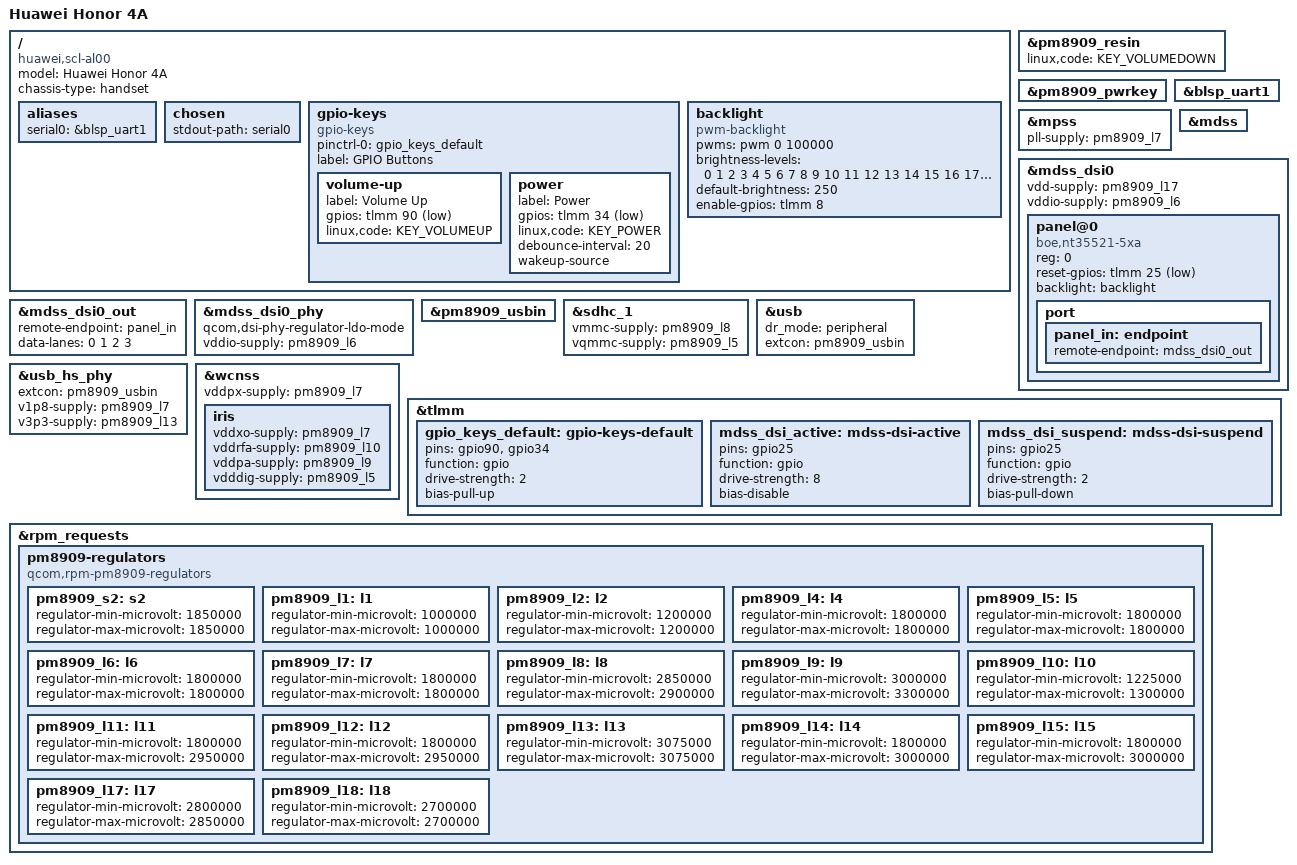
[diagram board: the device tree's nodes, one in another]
// SPDX-License-Identifier: GPL-2.0-only
/*
 * Copyright (c) 2022 Twodays <gunmu114514@outlook.com>
 */
#include "qcom-msm8909.dtsi"
#include "qcom-pm8909.dtsi"
#include <dt-bindings/input/input.h>
#include <dt-bindings/gpio/gpio.h>

/ {
	model = "Huawei Honor 4A";
	compatible = "huawei,scl-al00", "qcom,msm8909";
	chassis-type = "handset";

	aliases {
		serial0 = &blsp_uart1;
	};

	chosen {
		stdout-path = "serial0";
	};

	gpio-keys {
		compatible = "gpio-keys";

		pinctrl-names = "default";
		pinctrl-0 = <&gpio_keys_default>;

		label = "GPIO Buttons";

		volume-up {
			label = "Volume Up";
			gpios = <&tlmm 90 GPIO_ACTIVE_LOW>;
			linux,code = <KEY_VOLUMEUP>;
		};

		power {
			label = "Power";
			gpios = <&tlmm 34 GPIO_ACTIVE_LOW>;
			linux,code = <KEY_POWER>;
			debounce-interval = <20>;
			wakeup-source;
		};
	};

	backlight: backlight {
		compatible = "pwm-backlight";
		pwms = <&pwm 0 100000>;
		brightness-levels = <0 1 2 3 4 5 6 7 8 9 10 11 12 13 14 15
				     16 17 18 19 20 21 22 23 24 25 26 27 28 29 30
				     31 32 33 34 35 36 37 38 39 40 41 42 43 44 45
				     46 47 48 49 50 51 52 53 54 55 56 57 58 59 60
				     61 62 63 64 65 66 67 68 69 70 71 72 73 74 75
				     76 77 78 79 80 81 82 83 84 85 86 87 88 89 90
				     91 92 93 94 95 96 97 98 99 100 101 102 103 104
				     105 106 107 108 109 110 111 112 113 114 115 116
				     117 118 119 120 121 122 123 124 125 126 127 128
				     129 130 131 132 133 134 135 136 137 138 139 140
				     141 142 143 144 145 146 147 148 149 150 151 152
				     153 154 155 156 157 158 159 160 161 162 163 164
				     165 166 167 168 169 170 171 172 173 174 175 176
				     177 178 179 180 181 182 183 184 185 186 187 188
				     189 190 191 192 193 194 195 196 197 198 199 200
				     201 202 203 204 205 206 207 208 209 210 211 212
				     213 214 215 216 217 218 219 220 221 222 223 224
				     225 226 227 228 229 230 231 232 233 234 235 236
				     237 238 239 240 241 242 243 244 245 246 247 248
				     249 250>;
		default-brightness = <250>;
		enable-gpios = <&tlmm 8 GPIO_ACTIVE_HIGH>;
	};
};

&pm8909_resin {
	status = "okay";
	linux,code = <KEY_VOLUMEDOWN>;
};

&pm8909_pwrkey {
	status = "okay";
};

&blsp_uart1 {
	status = "okay";
};

&mpss {
	status = "okay";
	pll-supply = <&pm8909_l7>;
};

&mdss {
	status = "okay";
};

&mdss_dsi0 {
	status = "okay";
	vdd-supply = <&pm8909_l17>;
	vddio-supply = <&pm8909_l6>;
	
	#address-cells = <1>;
	#size-cells = <0>;
	
	panel@0 {
		compatible = "boe,nt35521-5xa";
		reg = <0>;
		
		reset-gpios = <&tlmm 25 GPIO_ACTIVE_LOW>;
		backlight = <&backlight>;
		
		port {
			panel_in: endpoint {
				remote-endpoint = <&mdss_dsi0_out>;
			};
		};
	};
};

&mdss_dsi0_out {
	remote-endpoint = <&panel_in>;
	data-lanes = <0 1 2 3>;
};

&mdss_dsi0_phy {
	status = "okay";
	qcom,dsi-phy-regulator-ldo-mode;
	vddio-supply = <&pm8909_l6>;
};

&pm8909_usbin {
	status = "okay";
};

&sdhc_1 {
	status = "okay";
	vmmc-supply = <&pm8909_l8>;
	vqmmc-supply = <&pm8909_l5>;
};

&usb {
	status = "okay";
	dr_mode = "peripheral";
	extcon = <&pm8909_usbin>;
};

&usb_hs_phy {
	extcon = <&pm8909_usbin>;
	v1p8-supply = <&pm8909_l7>;
	v3p3-supply = <&pm8909_l13>;
};

&wcnss {
	status = "okay";
	vddpx-supply = <&pm8909_l7>;

	iris {
		vddxo-supply = <&pm8909_l7>;
		vddrfa-supply = <&pm8909_l10>;
		vddpa-supply = <&pm8909_l9>;
		vdddig-supply = <&pm8909_l5>;
	};
};

&tlmm {
	gpio_keys_default: gpio-keys-default {
		pins = "gpio90", "gpio34";
		function = "gpio";

		drive-strength = <2>;
		bias-pull-up;
	};

	mdss_dsi_active: mdss-dsi-active {
		pins = "gpio25";
		function = "gpio";

		drive-strength = <8>;
		bias-disable;
	};

	mdss_dsi_suspend: mdss-dsi-suspend {
		pins = "gpio25";
		function = "gpio";

		drive-strength = <2>;
		bias-pull-down;
	};
};

&rpm_requests {
	pm8909-regulators {
		compatible = "qcom,rpm-pm8909-regulators";

		/* pm8909_s1 is managed by rpmpd (MSM8909_VDDCX) */
		pm8909_s2: s2 {
			regulator-min-microvolt = <1850000>;
			regulator-max-microvolt = <1850000>;
		};

		pm8909_l1: l1 {
			regulator-min-microvolt = <1000000>;
			regulator-max-microvolt = <1000000>;
		};
		pm8909_l2: l2 {
			regulator-min-microvolt = <1200000>;
			regulator-max-microvolt = <1200000>;
		};
		/* pm8909_l3 is managed by rpmpd (MSM8909_VDDMX) */
		pm8909_l4: l4 {
			regulator-min-microvolt = <1800000>;
			regulator-max-microvolt = <1800000>;
		};
		pm8909_l5: l5 {
			regulator-min-microvolt = <1800000>;
			regulator-max-microvolt = <1800000>;
		};
		pm8909_l6: l6 {
			regulator-min-microvolt = <1800000>;
			regulator-max-microvolt = <1800000>;
		};
		pm8909_l7: l7 {
			regulator-min-microvolt = <1800000>;
			regulator-max-microvolt = <1800000>;
		};
		pm8909_l8: l8 {
			regulator-min-microvolt = <2850000>;
			regulator-max-microvolt = <2900000>;
		};
		pm8909_l9: l9 {
			regulator-min-microvolt = <3000000>;
			regulator-max-microvolt = <3300000>;
		};
		pm8909_l10: l10 {
			regulator-min-microvolt = <1225000>;
			regulator-max-microvolt = <1300000>;
		};
		pm8909_l11: l11 {
			regulator-min-microvolt = <1800000>;
			regulator-max-microvolt = <2950000>;
		};
		pm8909_l12: l12 {
			regulator-min-microvolt = <1800000>;
			regulator-max-microvolt = <2950000>;
		};
		pm8909_l13: l13 {
			regulator-min-microvolt = <3075000>;
			regulator-max-microvolt = <3075000>;
		};
		pm8909_l14: l14 {
			regulator-min-microvolt = <1800000>;
			regulator-max-microvolt = <3000000>;
		};
		pm8909_l15: l15 {
			regulator-min-microvolt = <1800000>;
			regulator-max-microvolt = <3000000>;
		};
		pm8909_l17: l17 {
			regulator-min-microvolt = <2800000>;
			regulator-max-microvolt = <2850000>;
		};
		pm8909_l18: l18 {
			regulator-min-microvolt = <2700000>;
			regulator-max-microvolt = <2700000>;
		};
	};
};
